# R7FA4T1BB register map
Vendor: Renesas Electronics Corporation; Series: RA4; File version: 1.30.00
CPU: CM33 r0p4, little endian, MPU, FPU, VTOR, 4 interrupt priority bits, 96 interrupts
Registers are 32-bit, read-write, reset 0x0 unless marked. A register's access mark holds for its fields unless they carry their own. Offsets are from the block's base; [hi:lo] are bit positions; 'fields as' and 'values as' point back to an identical list.

## POEG — Port Output Enable Module for GPT
Base 0x4008A000
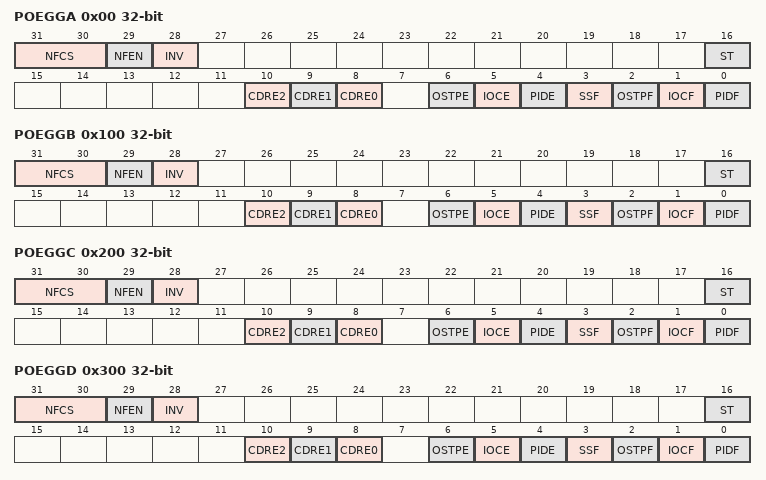
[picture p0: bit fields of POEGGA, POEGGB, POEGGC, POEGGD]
0x00 POEGGA — POEG Group A Setting Register
  [31:30] NFCS — Noise Filter Clock Select
    0=Sample GTETRGn pin input level three times every PCLKB; 1=Sample GTETRGn pin input level three times every PCLKB/8; 2=Sample GTETRGn pin input level three times every PCLKB/32; 3=Sample GTETRGn pin input level three times every PCLKB/128
  [29] NFEN — Noise Filter Enable
    0=Disable noise filtering; 1=Enable noise filtering
  [28] INV — GTETRGA Input Reverse
    0=Input GTETRGn as-is; 1=Input GTETRGn in reverse
  [16] ST ro — GTETRGA Input Status Flag
    0=GTETRGn input after filtering was 0; 1=GTETRGn input after filtering was 1
  [10] CDRE2
    0=Comparator 2 disable requests disabled; 1=Comparator 2 disable requests enabled
  [9] CDRE1
    0=Comparator 1 disable requests disabled; 1=Comparator 1 disable requests enabled
  [8] CDRE0
    0=Comparator 0 disable requests disabled; 1=Comparator 0 disable requests enabled
  [6] OSTPE — Oscillation Stop Detection Enable
    0=Disable output-disable requests from oscillation stop detection; 1=Enable output-disable requests from oscillation stop detection
  [5] IOCE — Enable for GPT Output-Disable Request
    0=Disable output-disable requests from GPT; 1=Enable output-disable requests from GPT
  [4] PIDE — Port Input Detection Enable
    0=Disable output-disable requests from the GTETRGn pins; 1=Enable output-disable requests from the GTETRGn pins
  [3] SSF — Software Stop Flag
    0=No output-disable request from software occurred; 1=Output-disable request from software occurred
  [2] OSTPF — Oscillation Stop Detection Flag
    0=No output-disable request from oscillation stop detection occurred; 1=Output-disable request from oscillation stop detection occurred
  [1] IOCF — Detection Flag for GPT Output-Disable Request
    0=No output-disable request from GPT or comparator interrupt occurred; 1=Output-disable request from GPT or comparator interrupt occurred
  [0] PIDF — Port Input Detection Flag
    0=No output-disable request from the GTETRGn pin occurred; 1=Output-disable request from the GTETRGn pin occurred
0x100 POEGGB — POEG Group B Setting Register
  [31:30] NFCS — Noise Filter Clock Select
    values as POEGGA.NFCS
  [29] NFEN — Noise Filter Enable
    0=Disable noise filtering; 1=Enable noise filtering
  [28] INV — GTETRGB Input Reverse
    0=Input GTETRGn as-is; 1=Input GTETRGn in reverse
  [16] ST ro — GTETRGB Input Status Flag
    values as POEGGA.ST
  [10] CDRE2
    values as POEGGA.CDRE2
  [9] CDRE1
    values as POEGGA.CDRE1
  [8] CDRE0
    values as POEGGA.CDRE0
  [6] OSTPE — Oscillation Stop Detection Enable
    values as POEGGA.OSTPE
  [5] IOCE — Enable for GPT Output-Disable Request
    values as POEGGA.IOCE
  [4] PIDE — Port Input Detection Enable
    values as POEGGA.PIDE
  [3] SSF — Software Stop Flag
    values as POEGGA.SSF
  [2] OSTPF — Oscillation Stop Detection Flag
    values as POEGGA.OSTPF
  [1] IOCF — Detection Flag for GPT Output-Disable Request
    values as POEGGA.IOCF
  [0] PIDF — Port Input Detection Flag
    values as POEGGA.PIDF
0x200 POEGGC — POEG Group C Setting Register
  [31:30] NFCS — Noise Filter Clock Select
    values as POEGGA.NFCS
  [29] NFEN — Noise Filter Enable
    0=Disable noise filtering; 1=Enable noise filtering
  [28] INV — GTETRGC Input Reverse
    0=Input GTETRGn as-is; 1=Input GTETRGn in reverse
  [16] ST ro — GTETRGC Input Status Flag
    values as POEGGA.ST
  [10] CDRE2
    values as POEGGA.CDRE2
  [9] CDRE1
    values as POEGGA.CDRE1
  [8] CDRE0
    values as POEGGA.CDRE0
  [6] OSTPE — Oscillation Stop Detection Enable
    values as POEGGA.OSTPE
  [5] IOCE — Enable for GPT Output-Disable Request
    values as POEGGA.IOCE
  [4] PIDE — Port Input Detection Enable
    values as POEGGA.PIDE
  [3] SSF — Software Stop Flag
    values as POEGGA.SSF
  [2] OSTPF — Oscillation Stop Detection Flag
    values as POEGGA.OSTPF
  [1] IOCF — Detection Flag for GPT Output-Disable Request
    values as POEGGA.IOCF
  [0] PIDF — Port Input Detection Flag
    values as POEGGA.PIDF
0x300 POEGGD — POEG Group D Setting Register
  [31:30] NFCS — Noise Filter Clock Select
    values as POEGGA.NFCS
  [29] NFEN — Noise Filter Enable
    0=Disable noise filtering; 1=Enable noise filtering
  [28] INV — GTETRGD Input Reverse
    0=Input GTETRGn as-is; 1=Input GTETRGn in reverse
  [16] ST ro — GTETRGD Input Status Flag
    values as POEGGA.ST
  [10] CDRE2
    values as POEGGA.CDRE2
  [9] CDRE1
    values as POEGGA.CDRE1
  [8] CDRE0
    values as POEGGA.CDRE0
  [6] OSTPE — Oscillation Stop Detection Enable
    values as POEGGA.OSTPE
  [5] IOCE — Enable for GPT Output-Disable Request
    values as POEGGA.IOCE
  [4] PIDE — Port Input Detection Enable
    values as POEGGA.PIDE
  [3] SSF — Software Stop Flag
    values as POEGGA.SSF
  [2] OSTPF — Oscillation Stop Detection Flag
    values as POEGGA.OSTPF
  [1] IOCF — Detection Flag for GPT Output-Disable Request
    values as POEGGA.IOCF
  [0] PIDF — Port Input Detection Flag
    values as POEGGA.PIDF

## Notices in the file
This software is supplied by Renesas Electronics Corporation and is only intended for
use with Renesas products. No other uses are authorized. This software is owned by
Renesas Electronics Corporation and is protected under all applicable laws, including
copyright laws.
THIS SOFTWARE IS PROVIDED "AS IS" AND RENESAS MAKES NO WARRANTIES REGARDING
THIS SOFTWARE, WHETHER EXPRESS, IMPLIED OR STATUTORY, INCLUDING BUT NOT LIMITED TO
WARRANTIES OF MERCHANTABILITY, FITNESS FOR A PARTICULAR PURPOSE AND NON-INFRINGEMENT.
ALL SUCH WARRANTIES ARE EXPRESSLY DISCLAIMED. TO THE MAXIMUM EXTENT PERMITTED NOT
PROHIBITED BY LAW, NEITHER RENESAS ELECTRONICS CORPORATION NOR ANY OF ITS AFFILIATED
COMPANIES SHALL BE LIABLE FOR ANY DIRECT, INDIRECT, SPECIAL, INCIDENTAL OR CONSEQUENTIAL
DAMAGES FOR ANY REASON RELATED TO THIS SOFTWARE, EVEN IF RENESAS OR ITS AFFILIATES HAVE
BEEN ADVISED OF THE POSSIBILITY OF SUCH DAMAGES.
Renesas reserves the right, without notice, to make changes to this software and to
discontinue the availability of this software. By using this software, you agree to
the additional terms and conditions found by accessing the following link:
http://www.renesas.com/disclaimer
